# STM32WLE5_CM4 register map
File version: 1.5
CPU: CM4 r0p1, little endian, MPU, FPU, 4 interrupt priority bits
Registers are 32-bit, read-write, reset 0x0 unless marked. A register's access mark holds for its fields unless they carry their own. Offsets are from the block's base; [hi:lo] are bit positions; {n}, {i} and the like mark numbered series; 'fields as' and 'values as' point back to an identical list.

## GPIOH — General-purpose I/Os
Base 0x48001C00
0x00 MODER reset 0xC0 — GPIO port mode register
  [7:6] MODER3 — Port x configuration bits (y = 0..15)
0x04 OTYPER — GPIO port output type register
  [3] OT3 — Port x configuration bits (y = 0..15)
0x08 OSPEEDR — GPIO port output speed register
  [7:6] OSPEEDR3 — Port x configuration bits (y = 0..15)
0x0C PUPDR — GPIO port pull-up/pull-down register
  [7:6] PUPDR3 — Port x configuration bits (y = 0..15)
0x10 IDR ro — GPIO port input data register
  [3] IDR3 — Port input data (y = 0..15)
0x14 ODR — GPIO port output data register
  [3] ODR3 — Port output data (y = 0..15)
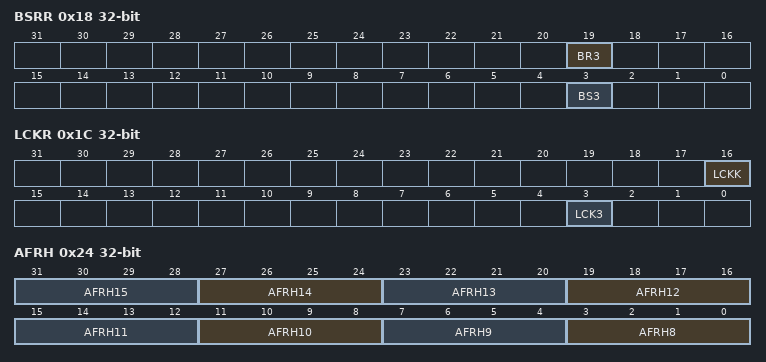
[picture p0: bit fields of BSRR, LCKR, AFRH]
0x18 BSRR wo — GPIO port bit set/reset register
  [19] BR3 — Port x reset bit y (y = 0..15)
  [3] BS3 — Port x set bit y (y= 0..15)
0x1C LCKR — GPIO port configuration lock register
  [16] LCKK — Port x lock bit y (y= 0..15)
  [3] LCK3 — Port x lock bit y (y= 0..15)
0x20 AFRL — GPIO alternate function low register
  [15:12] AFRL3 — Alternate function selection for port x bit y (y = 0..7)
0x24 AFRH — GPIO alternate function high register
  [4n-29:4n-32] AFRH{n} (n=8..15) — Alternate function selection for port x bit y (y = 8..15)
0x28 BRR — GPIO port bit reset register
  [3] BR3 — Port Reset bit

## HSEM — Hardware semaphore
Base 0x58001400
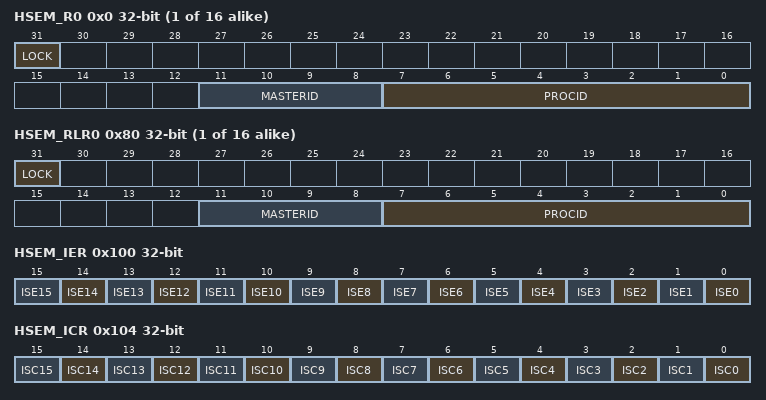
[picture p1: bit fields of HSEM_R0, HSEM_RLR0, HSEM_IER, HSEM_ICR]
{0x0+4i} HSEM_R{i} (i=0..15) — HSEM register HSEM_R0 HSEM_R31
  [31] LOCK — Lock indication
  [11:8] MASTERID — Semaphore MASTERID
  [7:0] PROCID — Semaphore ProcessID
{0x80+4i} HSEM_RLR{i} ro (i=0..15) — HSEM Read lock register
  fields as HSEM_R0
0x100 HSEM_IER — HSEM Interrupt enable register
  [n] ISE{n} (n=0..15) — Interrupt semaphore n enable bit
0x104 HSEM_ICR — HSEM Interrupt clear register
  [n] ISC{n} (n=0..15) — Interrupt(N) semaphore n clear bit
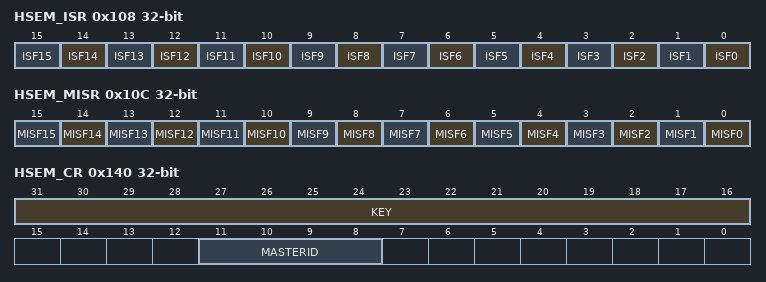
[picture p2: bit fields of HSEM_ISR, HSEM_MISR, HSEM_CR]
0x108 HSEM_ISR ro — HSEM Interrupt status register
  [n] ISF{n} (n=0..15) — Interrupt(N) semaphore n status bit before enable (mask)
0x10C HSEM_MISR ro — HSEM Masked interrupt status register
  [n] MISF{n} (n=0..15) — masked interrupt(N) semaphore n status bit after enable (mask)
0x140 HSEM_CR wo — HSEM Clear register
  [31:16] KEY — Semaphore clear Key
  [11:8] MASTERID
0x144 HSEM_KEYR — HSEM Interrupt clear register
  [31:16] KEY — Semaphore Clear Key

## IWDG — Independent watchdog
Base 0x40003000
0x00 KR wo — Key register
  [15:0] KEY — Key value (write only, read 0x0000)
0x04 PR reset 0x7 — Prescaler register
  [2:0] PR — Prescaler divider
0x08 RLR reset 0xFFF — Reload register
  [11:0] RL — Watchdog counter reload value
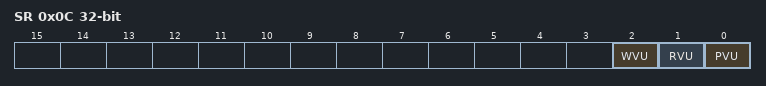
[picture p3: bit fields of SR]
0x0C SR ro — Status register
  [2] WVU — Watchdog counter window value update
  [1] RVU — Watchdog counter reload value update
  [0] PVU — Watchdog prescaler value update
0x10 WINR reset 0xFFF — Window register
  [11:0] WIN — Watchdog counter window value

## LPTIM1 — Low-power timer
Base 0x40007C00
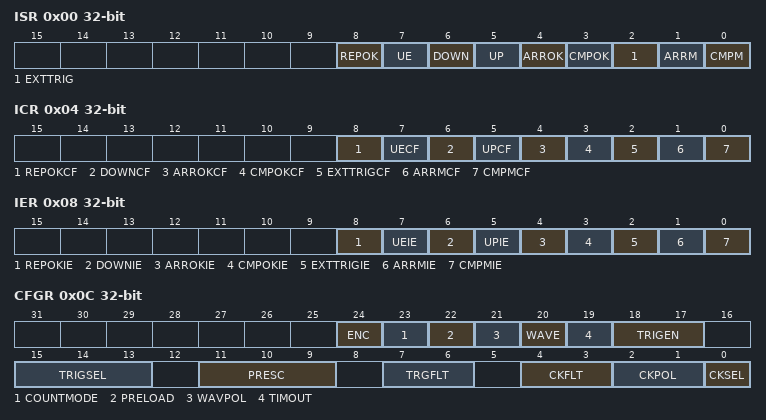
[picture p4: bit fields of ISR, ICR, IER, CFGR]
0x00 ISR ro — interrupt and status register
  [8] REPOK — Repetition register update Ok
  [7] UE — LPTIM update event occurred
  [6] DOWN — Counter direction change up to down
  [5] UP — Counter direction change down to up
  [4] ARROK — Autoreload register update OK
  [3] CMPOK — Compare register update OK
  [2] EXTTRIG — External trigger edge event
  [1] ARRM — Autoreload match
  [0] CMPM — Compare match
0x04 ICR wo — interrupt clear register
  [8] REPOKCF — Repetition register update OK clear flag
  [7] UECF — Update event clear flag
  [6] DOWNCF — Direction change to down Clear Flag
  [5] UPCF — Direction change to UP Clear Flag
  [4] ARROKCF — Autoreload register update OK Clear Flag
  [3] CMPOKCF — Compare register update OK Clear Flag
  [2] EXTTRIGCF — External trigger valid edge Clear Flag
  [1] ARRMCF — Autoreload match Clear Flag
  [0] CMPMCF — compare match Clear Flag
0x08 IER — interrupt enable register
  [8] REPOKIE — Repetition register update OK interrupt Enable
  [7] UEIE — Update event interrupt enable
  [6] DOWNIE — Direction change to down Interrupt Enable
  [5] UPIE — Direction change to UP Interrupt Enable
  [4] ARROKIE — Autoreload register update OK Interrupt Enable
  [3] CMPOKIE — Compare register update OK Interrupt Enable
  [2] EXTTRIGIE — External trigger valid edge Interrupt Enable
  [1] ARRMIE — Autoreload match Interrupt Enable
  [0] CMPMIE — Compare match Interrupt Enable
0x0C CFGR — configuration register
  [24] ENC, [23] COUNTMODE, [22] PRELOAD, [21] WAVPOL, [20] WAVE, [19] TIMOUT, [18:17] TRIGEN, [15:13] TRIGSEL, [11:9] PRESC, [7:6] TRGFLT, [4:3] CKFLT, [2:1] CKPOL, [0] CKSEL
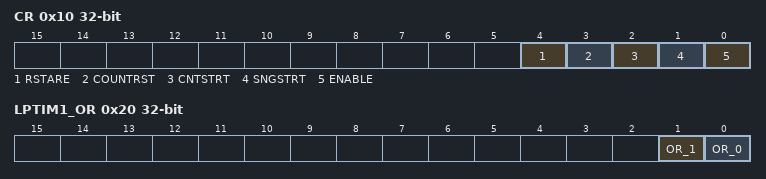
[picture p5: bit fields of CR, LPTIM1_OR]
0x10 CR — control register
  [4] RSTARE, [3] COUNTRST, [2] CNTSTRT, [1] SNGSTRT, [0] ENABLE
0x14 CMP — compare register
  [15:0] CMP
0x18 ARR reset 0x1 — autoreload register
  [15:0] ARR — Auto reload value
0x1C CNT ro — counter register
  [15:0] CNT — Counter value
0x20 LPTIM1_OR — option register
  [1] OR_1 — Option register bit 1
  [0] OR_0 — Option register bit 0
0x28 RCR — repetition register
  [7:0] REP — Repetition register value

## LPTIM2 — Low-power timer
Base 0x40009400
Registers as LPTIM1 (with LPTIM1 read as LPTIM2).

## LPTIM3 — Low-power timer
Base 0x40009800
Registers as LPTIM1 (with LPTIM1 read as LPTIM3).

## Notices in the file
Copyright (c) 2024 STMicroelectronics.
SPDX-License-Identifier: Apache-2.0
Licensed under the Apache License, Version 2.0 (the "License");
you may not use this file except in compliance with the License.
You may obtain a copy of the License at
http://www.apache.org/licenses/LICENSE-2.0
Unless required by applicable law or agreed to in writing, software
distributed under the License is distributed on an "AS IS" BASIS,
WITHOUT WARRANTIES OR CONDITIONS OF ANY KIND, either express or implied.
See the License for the specific language governing permissions and
limitations under the License.
